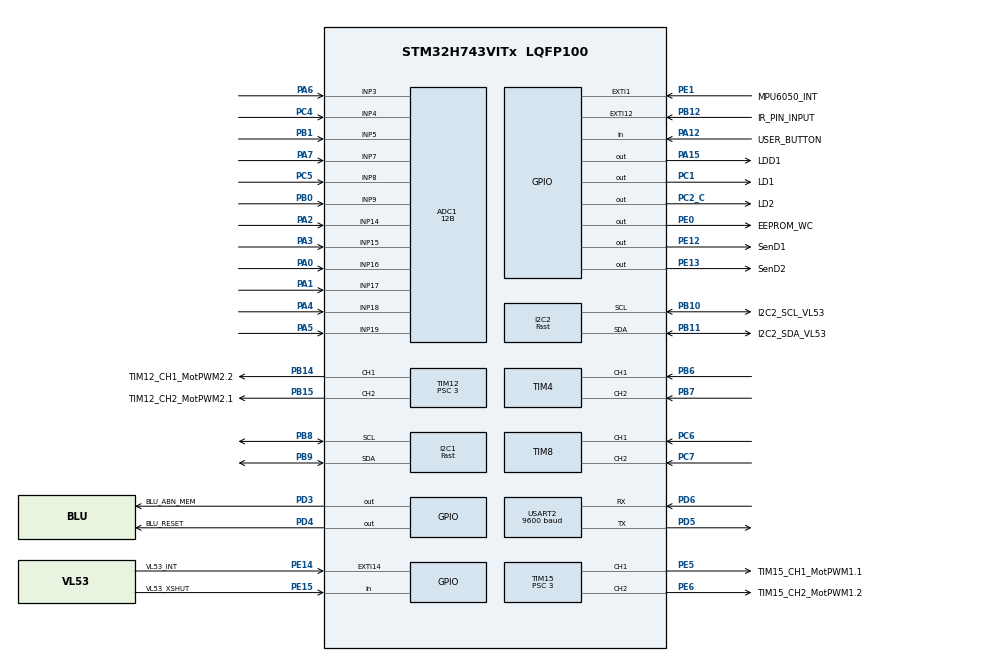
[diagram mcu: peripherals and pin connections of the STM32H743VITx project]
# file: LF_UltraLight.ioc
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ADC1.Channel-10\#ChannelRegularConversion=ADC_CHANNEL_14
ADC1.Channel-11\#ChannelRegularConversion=ADC_CHANNEL_15
ADC1.Channel-12\#ChannelRegularConversion=ADC_CHANNEL_18
ADC1.Channel-13\#ChannelRegularConversion=ADC_CHANNEL_19
ADC1.Channel-14\#ChannelRegularConversion=ADC_CHANNEL_3
ADC1.Channel-15\#ChannelRegularConversion=ADC_CHANNEL_7
ADC1.Channel-16\#ChannelRegularConversion=ADC_CHANNEL_4
ADC1.Channel-17\#ChannelRegularConversion=ADC_CHANNEL_8
ADC1.Channel-18\#ChannelRegularConversion=ADC_CHANNEL_9
ADC1.Channel-19\#ChannelRegularConversion=ADC_CHANNEL_5
ADC1.Channel-8\#ChannelRegularConversion=ADC_CHANNEL_16
ADC1.Channel-9\#ChannelRegularConversion=ADC_CHANNEL_17
ADC1.ClockPrescaler=ADC_CLOCK_ASYNC_DIV6
ADC1.ContinuousConvMode=ENABLE
ADC1.ConversionDataManagement=ADC_CONVERSIONDATA_DMA_CIRCULAR
ADC1.EnableInjectedConversion=ENABLE
ADC1.NbrOfConversion=12
ADC1.NbrOfConversionFlag=1
ADC1.OffsetNumber-10\#ChannelRegularConversion=ADC_OFFSET_NONE
ADC1.OffsetNumber-11\#ChannelRegularConversion=ADC_OFFSET_NONE
ADC1.OffsetNumber-12\#ChannelRegularConversion=ADC_OFFSET_NONE
ADC1.OffsetNumber-13\#ChannelRegularConversion=ADC_OFFSET_NONE
ADC1.OffsetNumber-14\#ChannelRegularConversion=ADC_OFFSET_NONE
ADC1.OffsetNumber-15\#ChannelRegularConversion=ADC_OFFSET_NONE
ADC1.OffsetNumber-16\#ChannelRegularConversion=ADC_OFFSET_NONE
ADC1.OffsetNumber-17\#ChannelRegularConversion=ADC_OFFSET_NONE
ADC1.OffsetNumber-18\#ChannelRegularConversion=ADC_OFFSET_NONE
ADC1.OffsetNumber-19\#ChannelRegularConversion=ADC_OFFSET_NONE
ADC1.OffsetNumber-8\#ChannelRegularConversion=ADC_OFFSET_NONE
ADC1.OffsetNumber-9\#ChannelRegularConversion=ADC_OFFSET_NONE
ADC1.Overrun=ADC_OVR_DATA_OVERWRITTEN
ADC1.OversamplingMode=DISABLE
ADC1.Rank-10\#ChannelRegularConversion=3
ADC1.Rank-11\#ChannelRegularConversion=4
ADC1.Rank-12\#ChannelRegularConversion=5
ADC1.Rank-13\#ChannelRegularConversion=6
ADC1.Rank-14\#ChannelRegularConversion=7
ADC1.Rank-15\#ChannelRegularConversion=8
ADC1.Rank-16\#ChannelRegularConversion=9
ADC1.Rank-17\#ChannelRegularConversion=10
ADC1.Rank-18\#ChannelRegularConversion=11
ADC1.Rank-19\#ChannelRegularConversion=12
ADC1.Rank-8\#ChannelRegularConversion=1
ADC1.Rank-9\#ChannelRegularConversion=2
ADC1.Resolution=ADC_RESOLUTION_12B
ADC1.SamplingTime-10\#ChannelRegularConversion=ADC_SAMPLETIME_16CYCLES_5
ADC1.SamplingTime-11\#ChannelRegularConversion=ADC_SAMPLETIME_16CYCLES_5
ADC1.SamplingTime-12\#ChannelRegularConversion=ADC_SAMPLETIME_16CYCLES_5
ADC1.SamplingTime-13\#ChannelRegularConversion=ADC_SAMPLETIME_16CYCLES_5
ADC1.SamplingTime-14\#ChannelRegularConversion=ADC_SAMPLETIME_16CYCLES_5
ADC1.SamplingTime-15\#ChannelRegularConversion=ADC_SAMPLETIME_16CYCLES_5
ADC1.SamplingTime-16\#ChannelRegularConversion=ADC_SAMPLETIME_16CYCLES_5
ADC1.SamplingTime-17\#ChannelRegularConversion=ADC_SAMPLETIME_16CYCLES_5
ADC1.SamplingTime-18\#ChannelRegularConversion=ADC_SAMPLETIME_16CYCLES_5
ADC1.SamplingTime-19\#ChannelRegularConversion=ADC_SAMPLETIME_16CYCLES_5
ADC1.SamplingTime-8\#ChannelRegularConversion=ADC_SAMPLETIME_16CYCLES_5
ADC1.SamplingTime-9\#ChannelRegularConversion=ADC_SAMPLETIME_16CYCLES_5
ADC1.master=1
CORTEX_M7.CPU_ICache=Disabled
Dma.ADC1.0.Direction=DMA_PERIPH_TO_MEMORY
Dma.ADC1.0.EventEnable=DISABLE
Dma.ADC1.0.FIFOMode=DMA_FIFOMODE_DISABLE
Dma.ADC1.0.Instance=DMA1_Stream0
Dma.ADC1.0.MemDataAlignment=DMA_MDATAALIGN_HALFWORD
Dma.ADC1.0.MemInc=DMA_MINC_ENABLE
Dma.ADC1.0.Mode=DMA_CIRCULAR
Dma.ADC1.0.PeriphDataAlignment=DMA_PDATAALIGN_HALFWORD
Dma.ADC1.0.PeriphInc=DMA_PINC_DISABLE
Dma.ADC1.0.Polarity=HAL_DMAMUX_REQ_GEN_RISING
Dma.ADC1.0.Priority=DMA_PRIORITY_LOW
Dma.ADC1.0.RequestNumber=1
Dma.ADC1.0.SignalID=NONE
Dma.ADC1.0.SyncEnable=DISABLE
Dma.ADC1.0.SyncPolarity=HAL_DMAMUX_SYNC_NO_EVENT
Dma.ADC1.0.SyncRequestNumber=1
Dma.ADC1.0.SyncSignalID=NONE
Dma.Request0=ADC1
Dma.Request1=USART2_RX
Dma.Request2=USART2_TX
Dma.USART2_RX.1.Direction=DMA_PERIPH_TO_MEMORY
Dma.USART2_RX.1.EventEnable=DISABLE
Dma.USART2_RX.1.FIFOMode=DMA_FIFOMODE_DISABLE
Dma.USART2_RX.1.Instance=DMA1_Stream1
Dma.USART2_RX.1.MemDataAlignment=DMA_MDATAALIGN_BYTE
Dma.USART2_RX.1.MemInc=DMA_MINC_ENABLE
Dma.USART2_RX.1.Mode=DMA_NORMAL
Dma.USART2_RX.1.PeriphDataAlignment=DMA_PDATAALIGN_BYTE
Dma.USART2_RX.1.PeriphInc=DMA_PINC_DISABLE
Dma.USART2_RX.1.Polarity=HAL_DMAMUX_REQ_GEN_RISING
Dma.USART2_RX.1.Priority=DMA_PRIORITY_LOW
Dma.USART2_RX.1.RequestNumber=1
Dma.USART2_RX.1.SignalID=NONE
Dma.USART2_RX.1.SyncEnable=DISABLE
Dma.USART2_RX.1.SyncPolarity=HAL_DMAMUX_SYNC_NO_EVENT
Dma.USART2_RX.1.SyncRequestNumber=1
Dma.USART2_RX.1.SyncSignalID=NONE
Dma.USART2_TX.2.Direction=DMA_MEMORY_TO_PERIPH
Dma.USART2_TX.2.EventEnable=DISABLE
Dma.USART2_TX.2.FIFOMode=DMA_FIFOMODE_DISABLE
Dma.USART2_TX.2.Instance=DMA1_Stream2
Dma.USART2_TX.2.MemDataAlignment=DMA_MDATAALIGN_BYTE
Dma.USART2_TX.2.MemInc=DMA_MINC_ENABLE
Dma.USART2_TX.2.Mode=DMA_NORMAL
Dma.USART2_TX.2.PeriphDataAlignment=DMA_PDATAALIGN_BYTE
Dma.USART2_TX.2.PeriphInc=DMA_PINC_DISABLE
Dma.USART2_TX.2.Polarity=HAL_DMAMUX_REQ_GEN_RISING
Dma.USART2_TX.2.Priority=DMA_PRIORITY_LOW
Dma.USART2_TX.2.RequestNumber=1
Dma.USART2_TX.2.SignalID=NONE
Dma.USART2_TX.2.SyncEnable=DISABLE
Dma.USART2_TX.2.SyncPolarity=HAL_DMAMUX_SYNC_NO_EVENT
Dma.USART2_TX.2.SyncRequestNumber=1
Dma.USART2_TX.2.SyncSignalID=NONE
I2C1.I2C_Speed_Mode=I2C_Fast
I2C1.Timing=0x009034B6
I2C2.I2C_Speed_Mode=I2C_Fast
I2C2.Timing=0x009034B6
Mcu.Family=STM32H7
Mcu.Name=STM32H743VITx
Mcu.Package=LQFP100
NVIC.DMA1_Stream0_IRQn=true\:0\:0\:false\:false\:true\:false\:true\:true
NVIC.DMA1_Stream1_IRQn=true\:0\:0\:false\:false\:true\:false\:true\:true
NVIC.DMA1_Stream2_IRQn=true\:0\:0\:false\:false\:true\:false\:true\:true
NVIC.EXTI15_10_IRQn=true\:0\:0\:false\:false\:true\:true\:true\:true
NVIC.I2C1_ER_IRQn=true\:0\:0\:false\:false\:true\:true\:true\:true
NVIC.I2C1_EV_IRQn=true\:0\:0\:false\:false\:true\:true\:true\:true
NVIC.I2C2_ER_IRQn=true\:0\:0\:false\:false\:true\:true\:true\:true
NVIC.I2C2_EV_IRQn=true\:0\:0\:false\:false\:true\:true\:true\:true
NVIC.PriorityGroup=NVIC_PRIORITYGROUP_4
NVIC.TIM2_IRQn=true\:13\:0\:true\:false\:true\:true\:true\:true
NVIC.TIM5_IRQn=true\:15\:0\:true\:false\:true\:true\:true\:true
NVIC.USART2_IRQn=true\:0\:0\:false\:false\:true\:true\:true\:true
PA0.Mode=IN16-Single-Ended
PA0.Signal=ADC1_INP16
PA1.Mode=IN17-Single-Ended
PA1.Signal=ADC1_INP17
PA12.GPIO_Label=USER_BUTTON
PA12.Signal=GPIO_Input
PA13\ (JTMS/SWDIO).Mode=Trace_Asynchronous_SW
PA13\ (JTMS/SWDIO).Signal=DEBUG_JTMS-SWDIO
PA14\ (JTCK/SWCLK).Mode=Trace_Asynchronous_SW
PA14\ (JTCK/SWCLK).Signal=DEBUG_JTCK-SWCLK
PA15\ (JTDI).GPIO_Label=LDD1
PA15\ (JTDI).GPIO_ModeDefaultOutputPP=GPIO_MODE_OUTPUT_OD
PA15\ (JTDI).PinState=GPIO_PIN_SET
PA15\ (JTDI).Signal=GPIO_Output
PA2.Signal=ADCx_INP14
PA3.Signal=ADCx_INP15
PA4.Signal=ADCx_INP18
PA5.Signal=ADCx_INP19
PA6.Signal=ADCx_INP3
PA7.Signal=ADCx_INP7
PB0.Signal=ADCx_INP9
PB1.Signal=ADCx_INP5
PB10.GPIO_Label=I2C2_SCL_VL53
PB10.Mode=I2C
PB10.Signal=I2C2_SCL
PB11.GPIO_Label=I2C2_SDA_VL53
PB11.Mode=I2C
PB11.Signal=I2C2_SDA
PB12.GPIO_Label=IR_PIN_INPUT
PB12.GPIO_ModeDefaultEXTI=GPIO_MODE_IT_FALLING
PB12.Signal=GPXTI12
PB14.GPIO_Label=TIM12_CH1_MotPWM2.2
PB14.Signal=S_TIM12_CH1
PB15.GPIO_Label=TIM12_CH2_MotPWM2.1
PB15.Signal=S_TIM12_CH2
PB3\ (JTDO/TRACESWO).Mode=Trace_Asynchronous_SW
PB3\ (JTDO/TRACESWO).Signal=DEBUG_JTDO-SWO
PB6.Signal=S_TIM4_CH1
PB7.Signal=S_TIM4_CH2
PB8.GPIO_Pu=GPIO_PULLUP
PB8.Mode=I2C
PB8.Signal=I2C1_SCL
PB9.GPIO_Pu=GPIO_PULLUP
PB9.Mode=I2C
PB9.Signal=I2C1_SDA
PC1.GPIO_Label=LD1
PC1.Signal=GPIO_Output
PC2_C.GPIO_Label=LD2
PC2_C.Signal=GPIO_Output
PC4.Signal=ADCx_INP4
PC5.Signal=ADCx_INP8
PC6.Signal=S_TIM8_CH1
PC7.Signal=S_TIM8_CH2
PD3.GPIO_Label=BLU_ABN_MEM
PD3.Signal=GPIO_Output
PD4.GPIO_Label=BLU_RESET
PD4.Signal=GPIO_Output
PD5.Mode=Asynchronous
PD5.Signal=USART2_TX
PD6.Mode=Asynchronous
PD6.Signal=USART2_RX
PE0.GPIO_Label=EEPROM_WC
PE0.PinState=GPIO_PIN_SET
PE0.Signal=GPIO_Output
PE1.GPIO_Label=MPU6050_INT
PE1.Signal=GPXTI1
PE12.GPIO_Label=SenD1
PE12.GPIO_ModeDefaultOutputPP=GPIO_MODE_OUTPUT_OD
PE12.PinState=GPIO_PIN_SET
PE12.Signal=GPIO_Output
PE13.GPIO_Label=SenD2
PE13.GPIO_ModeDefaultOutputPP=GPIO_MODE_OUTPUT_OD
PE13.PinState=GPIO_PIN_SET
PE13.Signal=GPIO_Output
PE14.GPIO_Label=VL53_INT
PE14.Signal=GPXTI14
PE15.GPIO_Label=VL53_XSHUT
PE15.Signal=GPIO_Input
PE5.GPIO_Label=TIM15_CH1_MotPWM1.1
PE5.Signal=S_TIM15_CH1
PE6.GPIO_Label=TIM15_CH2_MotPWM1.2
PE6.Signal=S_TIM15_CH2
ProjectManager.HeapSize=0x200
ProjectManager.StackSize=0x400
ProjectManager.TargetToolchain=STM32CubeIDE
RCC.ADCCLockSelection=RCC_ADCCLKSOURCE_CLKP
RCC.ADCFreq_Value=64000000
RCC.APB1Freq_Value=100000000
RCC.APB2Freq_Value=100000000
RCC.APB3Freq_Value=100000000
RCC.APB4Freq_Value=100000000
RCC.CortexFreq_Value=400000000
RCC.D1PPRE=RCC_APB3_DIV2
RCC.D2PPRE1=RCC_APB1_DIV2
RCC.D2PPRE2=RCC_APB2_DIV2
RCC.D3PPRE=RCC_APB4_DIV2
RCC.DIVM1=4
RCC.DIVM2=2
RCC.DIVN1=50
RCC.DIVN2=120
RCC.DIVP2=8
RCC.DIVQ1=16
RCC.DIVQ2=8
RCC.DIVR2=8
RCC.HCLKFreq_Value=200000000
RCC.HPRE=RCC_HCLK_DIV2
RCC.HSE_VALUE=16000000
RCC.SYSCLKFreq_VALUE=400000000
RCC.SYSCLKSource=RCC_SYSCLKSOURCE_PLLCLK
RCC.USBFreq_Value=50000000
SH.ADCx_INP14.0=ADC1_INP14,IN14-Single-Ended
SH.ADCx_INP15.0=ADC1_INP15,IN15-Single-Ended
SH.ADCx_INP18.0=ADC1_INP18,IN18-Single-Ended
SH.ADCx_INP19.0=ADC1_INP19,IN19-Single-Ended
SH.ADCx_INP3.0=ADC1_INP3,IN3-Single-Ended
SH.ADCx_INP4.0=ADC1_INP4,IN4-Single-Ended
SH.ADCx_INP5.0=ADC1_INP5,IN5-Single-Ended
SH.ADCx_INP7.0=ADC1_INP7,IN7-Single-Ended
SH.ADCx_INP8.0=ADC1_INP8,IN8-Single-Ended
SH.ADCx_INP9.0=ADC1_INP9,IN9-Single-Ended
SH.S_TIM12_CH1.0=TIM12_CH1,PWM Generation1 CH1
SH.S_TIM12_CH2.0=TIM12_CH2,PWM Generation2 CH2
SH.S_TIM15_CH1.0=TIM15_CH1,PWM Generation1 CH1
SH.S_TIM15_CH2.0=TIM15_CH2,PWM Generation2 CH2
SH.S_TIM4_CH1.0=TIM4_CH1,Encoder_Interface
SH.S_TIM4_CH2.0=TIM4_CH2,Encoder_Interface
SH.S_TIM8_CH1.0=TIM8_CH1,Encoder_Interface
SH.S_TIM8_CH2.0=TIM8_CH2,Encoder_Interface
TIM12.Channel-PWM\ Generation1\ CH1=TIM_CHANNEL_1
TIM12.Channel-PWM\ Generation2\ CH2=TIM_CHANNEL_2
TIM12.Period=1000
TIM12.Prescaler=3
TIM15.Channel-PWM\ Generation1\ CH1=TIM_CHANNEL_1
TIM15.Channel-PWM\ Generation2\ CH2=TIM_CHANNEL_2
TIM15.Period=1000
TIM15.Prescaler=3
TIM2.Period=101
TIM2.Prescaler=199
TIM4.EncoderMode=TIM_ENCODERMODE_TI12
TIM4.IC1Filter=10
TIM4.IC1Polarity=TIM_ICPOLARITY_RISING
TIM4.IC2Filter=10
TIM4.IC2Polarity=TIM_ICPOLARITY_RISING
TIM5.Period=10000
TIM5.Prescaler=199
TIM8.AutoReloadPreload=TIM_AUTORELOAD_PRELOAD_ENABLE
TIM8.EncoderMode=TIM_ENCODERMODE_TI12
TIM8.IC1Filter=10
TIM8.IC1Polarity=TIM_ICPOLARITY_RISING
TIM8.IC2Filter=10
TIM8.IC2Polarity=TIM_ICPOLARITY_RISING
USART2.BaudRate=9600
USART2.SwapParam=ADVFEATURE_SWAP_DISABLE
USART2.VirtualMode-Asynchronous=VM_ASYNC
VP_TIM12_VS_ClockSourceINT.Mode=Internal
VP_TIM15_VS_ClockSourceINT.Mode=Internal
VP_TIM2_VS_ClockSourceINT.Mode=Internal
VP_TIM5_VS_ClockSourceINT.Mode=Internal
board=custom

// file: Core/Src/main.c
/* USER CODE BEGIN Header */
/**
  ******************************************************************************
  * @file           : main.c
  * @brief          : Main program body
  ******************************************************************************
  * @attention
  *
  * <h2><center>&copy; Copyright (c) 2020 STMicroelectronics.
  * All rights reserved.</center></h2>
  *
  * This software component is licensed by ST under BSD 3-Clause license,
  * the "License"; You may not use this file except in compliance with the
  * License. You may obtain a copy of the License at:
  *                        opensource.org/licenses/BSD-3-Clause
  *
  ******************************************************************************
  */
/* USER CODE END Header */
#include "main.h"
#include "adc.h"
#include "dma.h"
#include "i2c.h"
#include "tim.h"
#include "usart.h"
#include "gpio.h"

/* USER CODE BEGIN Includes */
#include "LF_MainRunnable.h"

#include "stdio.h"

/* USER CODE END Includes */

void SystemClock_Config(void);
void PeriphCommonClock_Config(void);

int main(void)
{

  /* MCU Configuration--------------------------------------------------------*/

  /* Reset of all peripherals, Initializes the Flash interface and the Systick. */
  HAL_Init();

  /* USER CODE BEGIN Init */
   /* Unlock the Flash Program Erase controller */
   HAL_FLASH_Unlock();

  /* USER CODE END Init */

  /* Configure the system clock */
  SystemClock_Config();

/* Configure the peripherals common clocks */
  PeriphCommonClock_Config();

  /* Initialize all configured peripherals */
  MX_GPIO_Init();
  MX_DMA_Init();
  MX_ADC1_Init();
  MX_TIM15_Init();
  MX_USART2_UART_Init();
  MX_TIM2_Init();
  MX_I2C1_Init();
  MX_TIM5_Init();
  MX_I2C2_Init();
  MX_TIM12_Init();
  MX_TIM8_Init();
  MX_TIM4_Init();
  /* USER CODE BEGIN 2 */
  //Activate 100usTimer
  LL_TIM_EnableIT_CC1(TIM2);
  LL_TIM_EnableCounter(TIM2);

  LF_AppInit();

  /* USER CODE END 2 */

  /* Infinite loop */
  /* USER CODE BEGIN WHILE */
  while (1)
  {
    LF_AppTask();
    /* USER CODE END WHILE */

  }
}

void SystemClock_Config(void)
{
  RCC_OscInitTypeDef RCC_OscInitStruct = {0};
  RCC_ClkInitTypeDef RCC_ClkInitStruct = {0};

  /** Supply configuration update enable
  */
  HAL_PWREx_ConfigSupply(PWR_LDO_SUPPLY);

  /** Configure the main internal regulator output voltage
  */
  __HAL_PWR_VOLTAGESCALING_CONFIG(PWR_REGULATOR_VOLTAGE_SCALE1);

  while(!__HAL_PWR_GET_FLAG(PWR_FLAG_VOSRDY)) {}

  /** Initializes the RCC Oscillators according to the specified parameters
  * in the RCC_OscInitTypeDef structure.
  */
  RCC_OscInitStruct.OscillatorType = RCC_OSCILLATORTYPE_HSI;
  RCC_OscInitStruct.HSIState = RCC_HSI_DIV1;
  RCC_OscInitStruct.HSICalibrationValue = RCC_HSICALIBRATION_DEFAULT;
  RCC_OscInitStruct.PLL.PLLState = RCC_PLL_ON;
  RCC_OscInitStruct.PLL.PLLSource = RCC_PLLSOURCE_HSI;
  RCC_OscInitStruct.PLL.PLLM = 4;
  RCC_OscInitStruct.PLL.PLLN = 50;
  RCC_OscInitStruct.PLL.PLLP = 2;
  RCC_OscInitStruct.PLL.PLLQ = 16;
  RCC_OscInitStruct.PLL.PLLR = 2;
  RCC_OscInitStruct.PLL.PLLRGE = RCC_PLL1VCIRANGE_3;
  RCC_OscInitStruct.PLL.PLLVCOSEL = RCC_PLL1VCOWIDE;
  RCC_OscInitStruct.PLL.PLLFRACN = 0;
  if (HAL_RCC_OscConfig(&RCC_OscInitStruct) != HAL_OK)
  {
    Error_Handler();
  }

  /** Initializes the CPU, AHB and APB buses clocks
  */
  RCC_ClkInitStruct.ClockType = RCC_CLOCKTYPE_HCLK|RCC_CLOCKTYPE_SYSCLK
                              |RCC_CLOCKTYPE_PCLK1|RCC_CLOCKTYPE_PCLK2
                              |RCC_CLOCKTYPE_D3PCLK1|RCC_CLOCKTYPE_D1PCLK1;
  RCC_ClkInitStruct.SYSCLKSource = RCC_SYSCLKSOURCE_PLLCLK;
  RCC_ClkInitStruct.SYSCLKDivider = RCC_SYSCLK_DIV1;
  RCC_ClkInitStruct.AHBCLKDivider = RCC_HCLK_DIV2;
  RCC_ClkInitStruct.APB3CLKDivider = RCC_APB3_DIV2;
  RCC_ClkInitStruct.APB1CLKDivider = RCC_APB1_DIV2;
  RCC_ClkInitStruct.APB2CLKDivider = RCC_APB2_DIV2;
  RCC_ClkInitStruct.APB4CLKDivider = RCC_APB4_DIV2;

  if (HAL_RCC_ClockConfig(&RCC_ClkInitStruct, FLASH_LATENCY_2) != HAL_OK)
  {
    Error_Handler();
  }
}

void PeriphCommonClock_Config(void)
{
  RCC_PeriphCLKInitTypeDef PeriphClkInitStruct = {0};

  /** Initializes the peripherals clock
  */
  PeriphClkInitStruct.PeriphClockSelection = RCC_PERIPHCLK_CKPER;
  PeriphClkInitStruct.CkperClockSelection = RCC_CLKPSOURCE_HSI;
  if (HAL_RCCEx_PeriphCLKConfig(&PeriphClkInitStruct) != HAL_OK)
  {
    Error_Handler();
  }
}

void Error_Handler(void)
{
}
